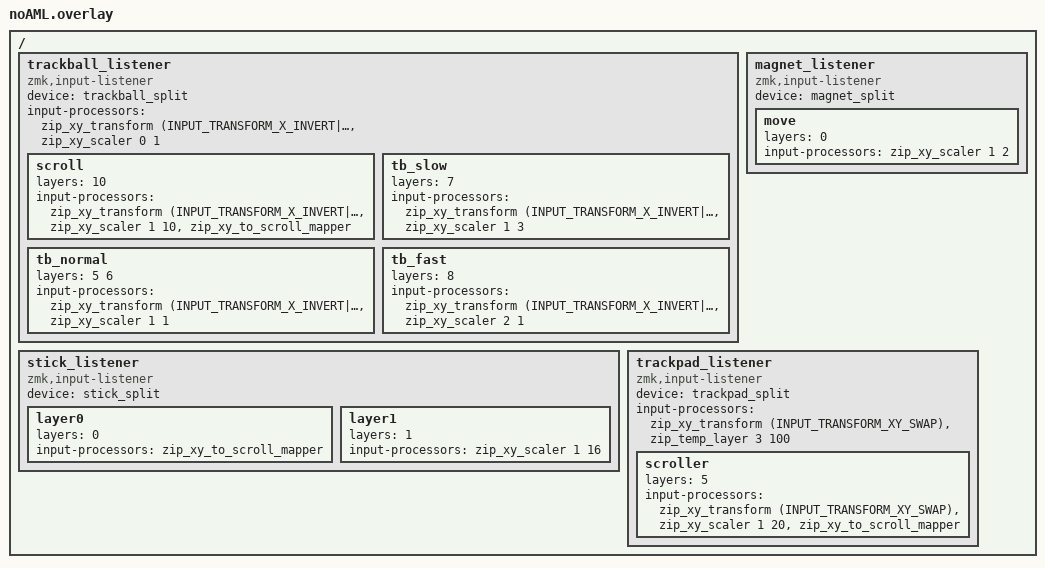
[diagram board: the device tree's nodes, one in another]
#define L_W_TB     5
#define L_M_TB     6
#define L_SLW_TB   7
#define L_FST_TB   8
#define L_SYS      10


/ {
    trackball_listener: trackball_listener {
        compatible = "zmk,input-listener";
        status = "okay";
        device = <&trackball_split>;

        /* デフォルト（＝通常の移動）。反転はここで共通適用 */
        input-processors = <
            &zip_xy_transform (INPUT_TRANSFORM_X_INVERT|INPUT_TRANSFORM_Y_INVERT)
            &zip_xy_scaler 0 1
        >;

        /* ★追加：SYS(10) のときはスクロールにする */

          scroll {
            layers = <10>;
            input-processors = <
                &zip_xy_transform (INPUT_TRANSFORM_X_INVERT|INPUT_TRANSFORM_Y_INVERT)
                &zip_xy_scaler 1 10
                &zip_xy_to_scroll_mapper
            >;
        };


        /* 遅い：SLW_TB */
        tb_slow {
            layers = <7>;
            input-processors = <
                &zip_xy_transform (INPUT_TRANSFORM_X_INVERT|INPUT_TRANSFORM_Y_INVERT)
                &zip_xy_scaler 1 3
            >;
        };

        /* 普通：W_TB と M_TB */
        tb_normal {
            layers = <5 6>;
            input-processors = <
                &zip_xy_transform (INPUT_TRANSFORM_X_INVERT|INPUT_TRANSFORM_Y_INVERT)
                &zip_xy_scaler 1 1
            >;
        };

        /* 速い：FST_TB */
        tb_fast {
            layers = <8>;
            input-processors = <
                &zip_xy_transform (INPUT_TRANSFORM_X_INVERT|INPUT_TRANSFORM_Y_INVERT)
                &zip_xy_scaler 2 1
            >;
        };


    };

    /* ★ここから magnet_listener（/ { } の外に出さない） */
    magnet_listener: magnet_listener {
        compatible = "zmk,input-listener";
        status = "okay";
        device = <&magnet_split>;

        move {
            layers = <0>;
            input-processors = <
                /* XYを入れ替えたいなら、下の行のコメントを外す（定義がある前提） */
                /* &zip_xy_transform (INPUT_TRANSFORM_XY_SWAP) */
                &zip_xy_scaler 1 2
            >;
        };
    };

    stick_listener: stick_listener {
        compatible = "zmk,input-listener";
        status = "okay";
        device = <&stick_split>;
        
        layer0 {
            layers = <0>;
            input-processors = <&zip_xy_to_scroll_mapper>;
        };
        layer1 {
            layers = <1>;
            input-processors = <&zip_xy_scaler 1 16>;
        };
    };
    
    trackpad_listener: trackpad_listener {
        compatible = "zmk,input-listener";
        status = "okay";
        device = <&trackpad_split>;
        
        input-processors = <
            &zip_xy_transform (INPUT_TRANSFORM_XY_SWAP)
            &zip_temp_layer 3 100
        >;

        scroller {
            layers = <5>;
            input-processors = <
                &zip_xy_transform (INPUT_TRANSFORM_XY_SWAP)
                &zip_xy_scaler 1 20
                &zip_xy_to_scroll_mapper
            >;
        };
    };
};
